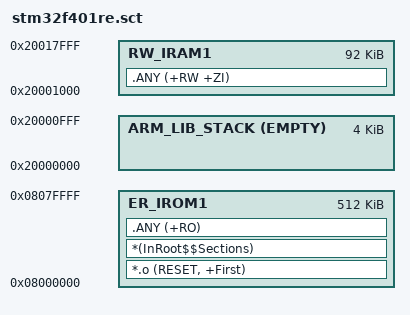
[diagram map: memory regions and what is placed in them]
; stm32f401re.sct : 512 KB flash at 0x08000000, 96 KB SRAM at 0x20000000
; The stack sits at the bottom of SRAM. An overflow runs below 0x20000000,
; so the simulator stops with error 65 there instead of corrupting data.

LR_IROM1 0x08000000 0x00080000 {
  ER_IROM1 0x08000000 0x00080000 {
    *.o (RESET, +First)
    *(InRoot$$Sections)
    .ANY (+RO)
  }
  ARM_LIB_STACK 0x20000000 EMPTY 0x00001000 {   ; 4 KB stack, SP starts at 0x20001000
  }
  RW_IRAM1 0x20001000 0x00017000 {              ; .data and .bss, remaining 92 KB
    .ANY (+RW +ZI)
  }
}
